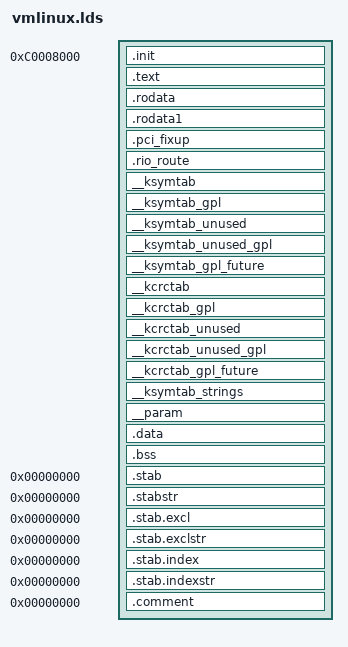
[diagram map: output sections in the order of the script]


/*
 * Automatically generated C config: don't edit
 * Linux kernel version: 2.6.19.2
 * Fri May 18 14:47:09 2012
 */
/* ld script to make ARM Linux kernel
 * taken from the i386 version by Russell King
 * Written by Martin Mares <mj@atrey.karlin.mff.cuni.cz>
 */
/* Align . to a 8 byte boundary equals to maximum function alignment. */
/* sched.text is aling to function alignment to secure we have same
 * address even at second ld pass when generating System.map */
/* spinlock.text is aling to function alignment to secure we have same
 * address even at second ld pass when generating System.map */
  /* DWARF debug sections.
		Symbols in the DWARF debugging sections are relative to
		the beginning of the section so we begin them at 0.  */
  /* Stabs debugging sections.  */
/*
 *  linux/include/asm-arm/thread_info.h
 *
 *  Copyright (C) 2002 Russell King.
 *
 * This program is free software; you can redistribute it and/or modify
 * it under the terms of the GNU General Public License version 2 as
 * published by the Free Software Foundation.
 */
/*
 * Allow us to mark functions as 'deprecated' and have gcc emit a nice
 * warning for each use, in hopes of speeding the functions removal.
 * Usage is:
 * 		int __deprecated foo(void)
 */
/*
 * Allow us to avoid 'defined but not used' warnings on functions and data,
 * as well as force them to be emitted to the assembly file.
 *
 * As of gcc 3.3, static functions that are not marked with attribute((used))
 * may be elided from the assembly file.  As of gcc 3.3, static data not so
 * marked will not be elided, but this may change in a future gcc version.
 *
 * In prior versions of gcc, such functions and data would be emitted, but
 * would be warned about except with attribute((unused)).
 */
/*
 * From the GCC manual:
 *
 * Many functions have no effects except the return value and their
 * return value depends only on the parameters and/or global
 * variables.  Such a function can be subject to common subexpression
 * elimination and loop optimization just as an arithmetic operator
 * would be.
 * [...]
 */
/*
 * From the GCC manual:
 *
 * Many functions do not examine any values except their arguments,
 * and have no effects except the return value.  Basically this is
 * just slightly more strict class than the `pure' attribute above,
 * since function is not allowed to read global memory.
 *
 * Note that a function that has pointer arguments and examines the
 * data pointed to must _not_ be declared `const'.  Likewise, a
 * function that calls a non-`const' function usually must not be
 * `const'.  It does not make sense for a `const' function to return
 * `void'.
 */
/*
 *  linux/include/asm-arm/fpstate.h
 *
 *  Copyright (C) 1995 Russell King
 *
 * This program is free software; you can redistribute it and/or modify
 * it under the terms of the GNU General Public License version 2 as
 * published by the Free Software Foundation.
 */
/*
 * We use bit 30 of the preempt_count to indicate that kernel
 * preemption is occurring.  See include/asm-arm/hardirq.h.
 */
/*
 * thread information flags:
 *  TIF_SYSCALL_TRACE	- syscall trace active
 *  TIF_NOTIFY_RESUME	- resumption notification requested
 *  TIF_SIGPENDING	- signal pending
 *  TIF_NEED_RESCHED	- rescheduling necessary
 *  TIF_USEDFPU		- FPU was used by this task this quantum (SMP)
 *  TIF_POLLING_NRFLAG	- true if poll_idle() is polling TIF_NEED_RESCHED
 */
/*
 * Change these and you break ASM code in entry-common.S
 */
/*
 *  linux/include/asm-arm/memory.h
 *
 *  Copyright (C) 2000-2002 Russell King
 *  modification for nommu, Hyok S. Choi, 2004
 *
 * This program is free software; you can redistribute it and/or modify
 * it under the terms of the GNU General Public License version 2 as
 * published by the Free Software Foundation.
 *
 *  Note: this file should not be included by non-asm/.h files
 */
/*
 * Allow for constants defined here to be used from assembly code
 * by prepending the UL suffix only with actual C code compilation.
 */
/*
 * Copyright 2004-2007 Freescale Semiconductor, Inc. All Rights Reserved.
 */
/*
 * The code contained herein is licensed under the GNU General Public
 * License. You may obtain a copy of the GNU General Public License
 * Version 2 or later at the following locations:
 *
 * http://www.opensource.org/licenses/gpl-license.html
 * http://www.gnu.org/copyleft/gpl.html
 */
/*
 *  Copyright 2004-2007 Freescale Semiconductor, Inc. All Rights Reserved.
 */
/*
 * The code contained herein is licensed under the GNU General Public
 * License. You may obtain a copy of the GNU General Public License
 * Version 2 or later at the following locations:
 *
 * http://www.opensource.org/licenses/gpl-license.html
 * http://www.gnu.org/copyleft/gpl.html
 */
/*!
 * @file arch-mxc/hardware.h
 * @brief This file contains the hardware definitions of the board.
 *
 * @ingroup MSL_MX27 MSL_MX31
 */
/*
 * This program is free software; you can redistribute it and/or modify
 * it under the terms of the GNU General Public License as published by
 * the Free Software Foundation; either version 2 of the License, or
 * (at your option) any later version.
 *
 * This program is distributed in the hope that it will be useful,
 * but WITHOUT ANY WARRANTY; without even the implied warranty of
 * MERCHANTABILITY or FITNESS FOR A PARTICULAR PURPOSE.  See the
 * GNU General Public License for more details.
 *
 * You should have received a copy of the GNU General Public License
 * along with this program; if not, write to the Free Software
 * Foundation, Inc., 59 Temple Place, Suite 330, Boston, MA  02111-1307  USA
 */
/* DO NOT EDIT!! - this file automatically generated
 *                 from .s file by awk -f s2h.awk
 */
/*  Size definitions
 *  Copyright (C) ARM Limited 1998. All rights reserved.
 */
/* handy sizes */
/*         END */
/*
 * This was automagically generated from arch/arm/tools/mach-types!
 * Do NOT edit
 */
/* see arch/arm/kernel/arch.c for a description of these */
/*
 * These have not yet been registered
 */
/* #define MACH_TYPE_367                  <<not registered>> */
/*!
 * defines PCIO_BASE (not used but needed for compilation)
 */
/*!
 * This macro is used to get certain bit field from a number
 */
/*!
 * This macro is used to set certain bit field inside a number
 */
/*
 * ---------------------------------------------------------------------------
 * Processor specific defines
 * ---------------------------------------------------------------------------
 */
/*
 * Copyright 2004-2007 Freescale Semiconductor, Inc. All Rights Reserved.
 */
/*
 * The code contained herein is licensed under the GNU General Public
 * License. You may obtain a copy of the GNU General Public License
 * Version 2 or later at the following locations:
 *
 * http://www.opensource.org/licenses/gpl-license.html
 * http://www.gnu.org/copyleft/gpl.html
 */
/*!
 * @file arch-mxc/mx27.h
 * @brief This file contains register definitions.
 *
 * @ingroup MSL_MX27
 */
/*
 * Copyright 2004-2007 Freescale Semiconductor, Inc. All Rights Reserved.
 */
/*
 * The code contained herein is licensed under the GNU General Public
 * License. You may obtain a copy of the GNU General Public License
 * Version 2 or later at the following locations:
 *
 * http://www.opensource.org/licenses/gpl-license.html
 * http://www.gnu.org/copyleft/gpl.html
 */
/*!
 * @file arch-mxc/mx27_pins.h
 *
 * @brief MX27 I/O Pin List
 *
 * @ingroup GPIO_MX27
 */
/*!
 * defines the OS clock tick rate
 */
/*!
 * Register an interrupt handler for the SMN as well as the SCC.  In some
 * implementations, the SMN is not connected at all, and in others, it is
 * on the same interrupt line as the SCM. Comment this line out accordingly
 */
/*!
 * UART Chip level Configuration that a user may not have to edit. These
 * configuration vary depending on how the UART module is integrated with
 * the ARM core
 */
/*!
 * This option is used to set or clear the RXDMUXSEL bit in control reg 3.
 * Certain platforms need this bit to be set in order to receive Irda data.
 */
/*!
 * This option is used to set or clear the RXDMUXSEL bit in control reg 3.
 * Certain platforms need this bit to be set in order to receive UART data.
 */
/*
 * IRAM
 */
/*
 *  Register offests.
 */
/* for mx27*/
/*
 * ROMP and AVIC
 */
/*
 * NAND, SDRAM, WEIM, M3IF, EMI controllers
 */
/*
 * Memory regions and CS
 */
/*!
 * This macro defines the physical to virtual address mapping for all the
 * peripheral modules. It is used by passing in the physical address as x
 * and returning the virtual address. If the physical address is not mapped,
 * it returns 0xDEADBEEF
 */
/*
 * define the address mapping macros: in physical address order
 */
/*
 *  MX27 ADS Interrupt numbers
 */
/*!
 * Number of GPIO port as defined in the IC Spec
 */
/*!
 * Number of GPIO pins per port
 */
/*!
 * NFMS bit in FMCR register for pagesize of nandflash
 */
/*
 * GPT clock source mask and offset bit definition
 */
/*
 * Copyright 2004-2007 Freescale Semiconductor, Inc. All Rights Reserved.
 */
/*
 * The code contained herein is licensed under the GNU General Public
 * License. You may obtain a copy of the GNU General Public License
 * Version 2 or later at the following locations:
 *
 * http://www.opensource.org/licenses/gpl-license.html
 * http://www.gnu.org/copyleft/gpl.html
 */
/*
 *****************************************
 * EPIT  Register definitions            *
 *****************************************
 */
/*
 *****************************************
 * GPT  Register definitions             *
 *****************************************
 */
/*
 *****************************************
 * AVIC Registers                        *
 *****************************************
 */
/*
 *****************************************
 * EDIO Registers                        *
 *****************************************
 */
/* DMA driver defines */
/*
 * ---------------------------------------------------------------------------
 * Board specific defines
 * ---------------------------------------------------------------------------
 */
/*
 * Copyright 2005-2007 Freescale Semiconductor, Inc. All Rights Reserved.
 */
/*
 * The code contained herein is licensed under the GNU General Public
 * License. You may obtain a copy of the GNU General Public License
 * Version 2 or later at the following locations:
 *
 * http://www.opensource.org/licenses/gpl-license.html
 * http://www.gnu.org/copyleft/gpl.html
 */
/*!
 * @defgroup BRDCFG_MX27 Board Configuration Options
 * @ingroup MSL_MX27
 */
/*!
 * @file arch-mxc/board-mx27mdk27v0.h
 *
 * @brief This file contains all the board level configuration options.
 *
 * It currently hold the options defined for MX27 MDK27V0 Platform.
 *
 * @ingroup BRDCFG_MX27
 */
/*
 * Include Files
 */
/*
 * Copyright 2004-2007 Freescale Semiconductor, Inc. All Rights Reserved.
 */
/*
 * The code contained herein is licensed under the GNU General Public
 * License. You may obtain a copy of the GNU General Public License
 * Version 2 or later at the following locations:
 *
 * http://www.opensource.org/licenses/gpl-license.html
 * http://www.gnu.org/copyleft/gpl.html
 */
/*
 * The modes of the UART ports
 */
/*
 * Is the UART configured to be a IR port
 */
/* Start of physical RAM */
/* Size of contiguous memory for DMA and other h/w blocks */
/*!
 * @name MXC UART EVB board level configurations
 */
/*! @{ */
/*!
 * Specify the max baudrate for the MXC UARTs for your board, do not specify a max
 * baudrate greater than 1500000. This is used while specifying the UART Power
 * management constraints.
 */
/*!
 * Specifies if the Irda transmit path is inverting
 */
/*!
 * Specifies if the Irda receive path is inverting
 */
/* UART 1 configuration */
/*!
 * This define specifies if the UART port is configured to be in DTE or
 * DCE mode. There exists a define like this for each UART port. Valid
 * values that can be used are \b MODE_DTE or \b MODE_DCE.
 */
/*!
 * This define specifies if the UART is to be used for IRDA. There exists a
 * define like this for each UART port. Valid values that can be used are
 * \b IRDA or \b NO_IRDA.
 */
/*!
 * This define is used to enable or disable a particular UART port. If
 * disabled, the UART will not be registered in the file system and the user
 * will not be able to access it. There exists a define like this for each UART
 * port. Specify a value of 1 to enable the UART and 0 to disable it.
 */
/*! @} */
/* UART 2 configuration */
/* UART 3 configuration */
/* UART 4 configuration */
/* UART 5 configuration */
/* UART 6 configuration */
/*!
 * @name Memory Size parameters
 */
/*! @{ */
/*!
 * Size of SDRAM memory
 */
/*! @} */
/*! @{ */
/*!
 * @name Keypad Configurations
 */
/*! @{ */
/*!
 * Maximum number of rows (0 to 7)
 */
/*!
 * Maximum number of columns (0 to 7)
 */
/*! @} */
/*!
 * Base address of PBC controller, CS5
 */
/* For interrupts like xuart, enet etc */
/* TODO:: */
/*
 *
 */
/*! This is System IRQ used by LAN9217 for interrupt generation taken from platform.h */
/*! This is I/O Base address used to access registers of CS8900A on MXC ADS */
/*! This is System IRQ used by CS8900A for interrupt generation */
/*! This is I/O Base address used to access registers of CS8900A on MDK27V1 */
/*! Definitions about CPLD signature*/
/*
 *  linux/include/asm-arm/page.h
 *
 *  Copyright (C) 1995-2003 Russell King
 *
 * This program is free software; you can redistribute it and/or modify
 * it under the terms of the GNU General Public License version 2 as
 * published by the Free Software Foundation.
 */
/* PAGE_SHIFT determines the page size */
/* to align the pointer to the (next) page boundary */
/*
 * With EABI on ARMv5 and above we must have 64-bit aligned slab pointers.
 */
/*!
 * @defgroup Memory_MX27 Memory Map
 * @ingroup MSL_MX27
 */
/*!
 * @defgroup Memory_MX31 Memory Map
 * @ingroup MSL_MX31
 */
/*!
 * @file arch-mxc/memory.h
 * @brief This file contains macros needed by the Linux kernel and drivers.
 *
 * @ingroup Memory_MX27 Memory_MX31
 */
/*!
 * Virtual view <-> DMA view memory address translations
 * This macro is used to translate the virtual address to an address
 * suitable to be passed to set_dma_addr()
 */
/*!
 * Used to convert an address for DMA operations to an address that the
 * kernel can use.
 */
/*
 * This program is free software; you can redistribute it and/or modify
 * it under the terms of the GNU General Public License as published by
 * the Free Software Foundation; either version 2 of the License, or
 * (at your option) any later version.
 *
 * This program is distributed in the hope that it will be useful,
 * but WITHOUT ANY WARRANTY; without even the implied warranty of
 * MERCHANTABILITY or FITNESS FOR A PARTICULAR PURPOSE.  See the
 * GNU General Public License for more details.
 *
 * You should have received a copy of the GNU General Public License
 * along with this program; if not, write to the Free Software
 * Foundation, Inc., 59 Temple Place, Suite 330, Boston, MA  02111-1307  USA
 */
/* DO NOT EDIT!! - this file automatically generated
 *                 from .s file by awk -f s2h.awk
 */
/*  Size definitions
 *  Copyright (C) ARM Limited 1998. All rights reserved.
 */
/*         END */
/*
 * TASK_SIZE - the maximum size of a user space task.
 * TASK_UNMAPPED_BASE - the lower boundary of the mmap VM area
 */
/*
 * The maximum size of a 26-bit user space task.
 */
/*
 * Page offset: 3GB
 */
/*
 * The module space lives between the addresses given by TASK_SIZE
 * and PAGE_OFFSET - it must be within 32MB of the kernel text.
 */
/*
 * The XIP kernel gets mapped at the bottom of the module vm area.
 * Since we use sections to map it, this macro replaces the physical address
 * with its virtual address while keeping offset from the base section.
 */
/*
 * Allow 16MB-aligned ioremap pages
 */
/*
 * Size of DMA-consistent memory region.  Must be multiple of 2M,
 * between 2MB and 14MB inclusive.
 */
/*
 * Physical vs virtual RAM address space conversion.  These are
 * private definitions which should NOT be used outside memory.h
 * files.  Use virt_to_phys/phys_to_virt/__pa/__va instead.
 */
/*
 * Convert a physical address to a Page Frame Number and back
 */
OUTPUT_ARCH(arm)
ENTRY(stext)
jiffies = jiffies_64;
SECTIONS
{
 . = (0xc0000000) + 0x00008000;
 .init : { /* Init code and data		*/
  _stext = .;
   _sinittext = .;
   *(.init.text)
   _einittext = .;
  __proc_info_begin = .;
   *(.proc.info.init)
  __proc_info_end = .;
  __arch_info_begin = .;
   *(.arch.info.init)
  __arch_info_end = .;
  __tagtable_begin = .;
   *(.taglist.init)
  __tagtable_end = .;
  . = ALIGN(16);
  __setup_start = .;
   *(.init.setup)
  __setup_end = .;
  __early_begin = .;
   *(.early_param.init)
  __early_end = .;
  __initcall_start = .;
   *(.initcall0.init) *(.initcall0s.init) *(.initcall1.init) *(.initcall1s.init) *(.initcall2.init) *(.initcall2s.init) *(.initcall3.init) *(.initcall3s.init) *(.initcall4.init) *(.initcall4s.init) *(.initcall5.init) *(.initcall5s.init) *(.initcall6.init) *(.initcall6s.init) *(.initcall7.init) *(.initcall7s.init)
  __initcall_end = .;
  __con_initcall_start = .;
   *(.con_initcall.init)
  __con_initcall_end = .;
  __security_initcall_start = .;
   *(.security_initcall.init)
  __security_initcall_end = .;
  . = ALIGN(32);
  __initramfs_start = .;
   usr/built-in.o(.init.ramfs)
  __initramfs_end = .;
  . = ALIGN(64);
  __per_cpu_start = .;
   *(.data.percpu)
  __per_cpu_end = .;
  __init_begin = _stext;
  *(.init.data)
  . = ALIGN(4096);
  __init_end = .;
 }
 /DISCARD/ : { /* Exit code and data		*/
  *(.exit.text)
  *(.exit.data)
  *(.exitcall.exit)
 }
 .text : { /* Real text segment		*/
  _text = .; /* Text and read-only data	*/
   *(.text)
   . = ALIGN(8); __sched_text_start = .; *(.sched.text) __sched_text_end = .;
   . = ALIGN(8); __lock_text_start = .; *(.spinlock.text) __lock_text_end = .;
   *(.fixup)
   *(.gnu.warning)
   *(.rodata)
   *(.rodata.*)
   *(.glue_7)
   *(.glue_7t)
  *(.got) /* Global offset table		*/
 }
 . = ALIGN(4096); __start_rodata = .; .rodata : AT(ADDR(.rodata) - 0) { *(.rodata) *(.rodata.*) *(__vermagic) } .rodata1 : AT(ADDR(.rodata1) - 0) { *(.rodata1) } .pci_fixup : AT(ADDR(.pci_fixup) - 0) { __start_pci_fixups_early = .; *(.pci_fixup_early) __end_pci_fixups_early = .; __start_pci_fixups_header = .; *(.pci_fixup_header) __end_pci_fixups_header = .; __start_pci_fixups_final = .; *(.pci_fixup_final) __end_pci_fixups_final = .; __start_pci_fixups_enable = .; *(.pci_fixup_enable) __end_pci_fixups_enable = .; } .rio_route : AT(ADDR(.rio_route) - 0) { __start_rio_route_ops = .; *(.rio_route_ops) __end_rio_route_ops = .; } __ksymtab : AT(ADDR(__ksymtab) - 0) { __start___ksymtab = .; *(__ksymtab) __stop___ksymtab = .; } __ksymtab_gpl : AT(ADDR(__ksymtab_gpl) - 0) { __start___ksymtab_gpl = .; *(__ksymtab_gpl) __stop___ksymtab_gpl = .; } __ksymtab_unused : AT(ADDR(__ksymtab_unused) - 0) { __start___ksymtab_unused = .; *(__ksymtab_unused) __stop___ksymtab_unused = .; } __ksymtab_unused_gpl : AT(ADDR(__ksymtab_unused_gpl) - 0) { __start___ksymtab_unused_gpl = .; *(__ksymtab_unused_gpl) __stop___ksymtab_unused_gpl = .; } __ksymtab_gpl_future : AT(ADDR(__ksymtab_gpl_future) - 0) { __start___ksymtab_gpl_future = .; *(__ksymtab_gpl_future) __stop___ksymtab_gpl_future = .; } __kcrctab : AT(ADDR(__kcrctab) - 0) { __start___kcrctab = .; *(__kcrctab) __stop___kcrctab = .; } __kcrctab_gpl : AT(ADDR(__kcrctab_gpl) - 0) { __start___kcrctab_gpl = .; *(__kcrctab_gpl) __stop___kcrctab_gpl = .; } __kcrctab_unused : AT(ADDR(__kcrctab_unused) - 0) { __start___kcrctab_unused = .; *(__kcrctab_unused) __stop___kcrctab_unused = .; } __kcrctab_unused_gpl : AT(ADDR(__kcrctab_unused_gpl) - 0) { __start___kcrctab_unused_gpl = .; *(__kcrctab_unused_gpl) __stop___kcrctab_unused_gpl = .; } __kcrctab_gpl_future : AT(ADDR(__kcrctab_gpl_future) - 0) { __start___kcrctab_gpl_future = .; *(__kcrctab_gpl_future) __stop___kcrctab_gpl_future = .; } __ksymtab_strings : AT(ADDR(__ksymtab_strings) - 0) { *(__ksymtab_strings) } __param : AT(ADDR(__param) - 0) { __start___param = .; *(__param) __stop___param = .; } __end_rodata = .; . = ALIGN(4096);
 _etext = .; /* End of text and rodata section */
 . = ALIGN(8192);
 __data_loc = .;
 .data : AT(__data_loc) {
  __data_start = .; /* address in memory */
  /*
		 * first, the init task union, aligned
		 * to an 8192 byte boundary.
		 */
  *(.init.task)
  . = ALIGN(4096);
  __nosave_begin = .;
  *(.data.nosave)
  . = ALIGN(4096);
  __nosave_end = .;
  /*
		 * then the cacheline aligned data
		 */
  . = ALIGN(32);
  *(.data.cacheline_aligned)
  /*
		 * The exception fixup table (might need resorting at runtime)
		 */
  . = ALIGN(32);
  __start___ex_table = .;
  *(__ex_table)
  __stop___ex_table = .;
  /*
		 * and the usual data section
		 */
  *(.data)
  CONSTRUCTORS
  _edata = .;
 }
 .bss : {
  __bss_start = .; /* BSS				*/
  *(.bss)
  *(COMMON)
  _end = .;
 }
     /* Stabs debugging sections.	*/
 .stab 0 : { *(.stab) }
 .stabstr 0 : { *(.stabstr) }
 .stab.excl 0 : { *(.stab.excl) }
 .stab.exclstr 0 : { *(.stab.exclstr) }
 .stab.index 0 : { *(.stab.index) }
 .stab.indexstr 0 : { *(.stab.indexstr) }
 .comment 0 : { *(.comment) }
}
/*
 * These must never be empty
 * If you have to comment these two assert statements out, your
 * binutils is too old (for other reasons as well)
 */
ASSERT((__proc_info_end - __proc_info_begin), "missing CPU support")
ASSERT((__arch_info_end - __arch_info_begin), "no machine record defined")
